# MM32P0xx register map
Vendor: MindMotion Ltd.; Series: MM32P0; File version: 1.4
MindMotion 32-bit Cortex-M0 Microcontroller based device, CPU clock up to 16 MHz, etc.
CPU: CM0 r0p0, little endian, no MPU, no FPU, 3 interrupt priority bits
Registers are 32-bit, read-write, reset 0x0 unless marked. A register's access mark holds for its fields unless they carry their own. Offsets are from the block's base; lines under a group give offsets from that group; [hi:lo] are bit positions; {n}, {i} and the like mark numbered series; 'fields as' and 'values as' point back to an identical list; <NAME> marks a mode.

## Memory map
0x40000000 TIM2 size 0x400 — General purpose timer
0x40000400 TIM3 size 0x400
0x40002C00 WWDG size 0x400 — Window watchdog
0x40003000 IWDG size 0x400 — Independent watchdog
0x40005400 I2C1 size 0x400 — Inter integrated circuit
0x40007000 PWR size 0x400 — Power control
0x40010000 SYSCFG size 0x400
0x40010400 EXTI size 0x400
0x40012400 ADC size 0x400 — Analog to digital converter
0x40012C00 TIM1 size 0x400 — Advanced timer
0x40013000 SPI1 size 0x400 — Serial peripheral interface
0x40013800 UART1 size 0x400 — Universal asynchronous receiver transmitter
0x40014000 TIM14 size 0x400 — Advanced timer
0x40014400 TIM16 size 0x400 — Advanced timer
0x40014800 TIM17 size 0x400
0x40020000 DMA size 0x400 — DMA controller
0x40021000 RCC size 0x400 — Reset and clock control
0x40022000 FLASH size 0x400
0x48000000 GPIOA size 0x400 — General purpose I/O
0x48000400 GPIOB size 0x400
0x48000800 GPIOC size 0x400
0x48000C00 GPIOD size 0x400
0xE0042000 DBG size 0x400 — Debug support

## Interrupts
0 WWDG — Window Watchdog interrupt
1 PVD (PWR) — PVD through EXTI line detection interrupt
3 FLASH — Flash global interrupt
4 RCC — RCC global interrupt
5 EXTI0_1 (EXTI) — EXTI Line0 interrupt
6 EXTI2_3 (EXTI) — EXTI Line1 interrupt
7 EXTI4_15 (EXTI) — EXTI Line2 interrupt
9 DMA_Channel1 (DMA) — DMA Channel1 global interrupt
10 DMA_Channel2 (DMA) — DMA Channel2 global interrupt
11 DMA_Channel4 (DMA) — DMA Channel4 global interrupt
12 ADC — ADC1 global interrupt
13 DMA_Channel3 (DMA) — DMA Channel3 global interrupt
14 TIM1_CC (TIM1) — TIM1 Capture Compare interrupt
19 TIM14_0 (TIM14) — TIM14 global interrupt
21 TIM14_1 (TIM14) — TIM14 global interrupt
22 TIM16 — TIM16 global interrupt
23 TIM17 — TIM17 global interrupt
25 SPI1 — SPI1 global interrupt
27 UART1 — UART1 global interrupt
28 TIM2 — TIM2 global interrupt
29 TIM3 — TIM3 global interrupt
31 I2C1_EV (I2C1) — I2C1 event interrupt

## SYSCFG
Base 0x40010000
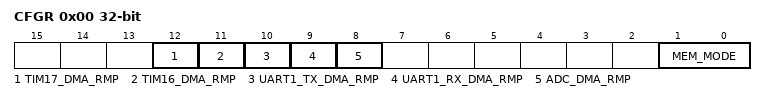
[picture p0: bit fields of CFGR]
0x00 CFGR
  [12] TIM17_DMA_RMP, [11] TIM16_DMA_RMP, [10] UART1_TX_DMA_RMP, [9] UART1_RX_DMA_RMP, [8] ADC_DMA_RMP, [1:0] MEM_MODE
{0x4+4i} EXTICR{i} (i=1..4)
  [15:0] EXTI{4i-1}

## EXTI
Base 0x40010400
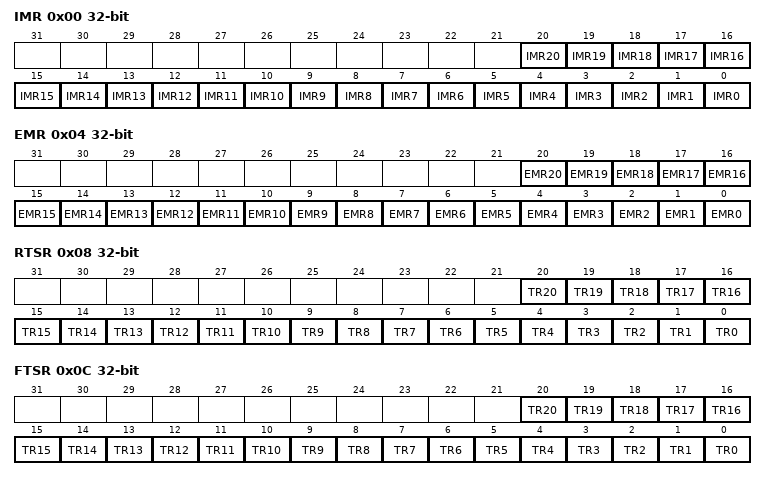
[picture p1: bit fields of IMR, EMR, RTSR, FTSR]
0x00 IMR
  [n] IMR{n} (n=0..20) — Interrupt Mask on line {n}
0x04 EMR
  [n] EMR{n} (n=0..20) — Event Mask on line {n}
0x08 RTSR
  [n] TR{n} (n=0..20) — Rising trigger event configuration bit of line {n}
0x0C FTSR
  [n] TR{n} (n=0..20) — Falling trigger event configuration bit of line {n}
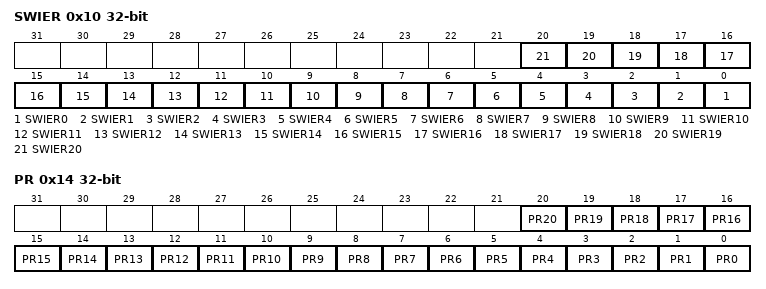
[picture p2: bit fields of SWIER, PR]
0x10 SWIER
  [n] SWIER{n} (n=0..20) — Software interrupt on line {n}
0x14 PR
  [n] PR{n} (n=0..20) — Pending bit

## DMA — DMA controller
Base 0x40020000
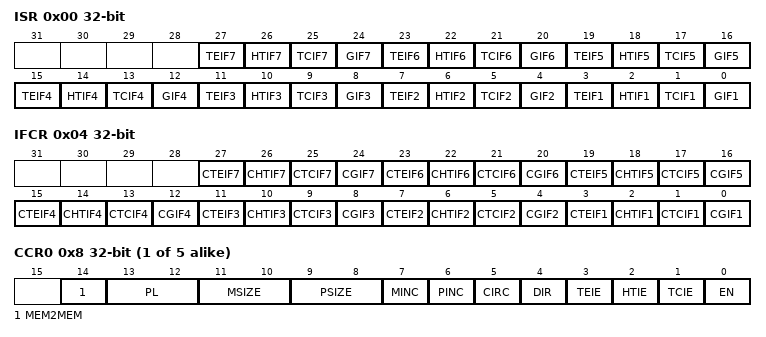
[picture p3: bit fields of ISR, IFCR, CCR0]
0x00 ISR ro
  [4n-1] TEIF{n} (n=1..7) — channel {n} transfer error flag
  [4n-2] HTIF{n} (n=1..7) — channel {n} half transfer flag
  [4n-3] TCIF{n} (n=1..7) — channel {n} half complete flag
  [4n-4] GIF{n} (n=1..7) — channel {n} global interrupt flag
0x04 IFCR ro
  [4n-1] CTEIF{n} (n=1..7) — channel {n} transfer error clear
  [4n-2] CHTIF{n} (n=1..7) — channel {n} half transfer clear
  [4n-3] CTCIF{n} (n=1..7) — channel {n} half complete clear
  [4n-4] CGIF{n} (n=1..7) — channel {n} global interrupt clear
{0x8+0x14*i} CCR{i} (i=0..4)
  [14] MEM2MEM — Memory to memory mode
  [13:12] PL — Channel priority level
  [11:10] MSIZE — Memory size
  [9:8] PSIZE — Peripheral size
  [7] MINC — Memory increment mode
  [6] PINC — Peripheral increment mode
  [5] CIRC — Circular mode
  [4] DIR — Data transfer direction
  [3] TEIE — Transfer error interrupt enable
  [2] HTIE — Half transfer interrupt enable
  [1] TCIE — Transfer complete interrupt enable
  [0] EN — Channel enable
{0xC+0x14*i} CNDTR{i} (i=0..4)
  [15:0] NDT — Number of data to transfer
{0x10+0x14*i} CPAR{i} (i=0..4)
  [31:0] PA — Peripheral address
{0x14+0x14*i} CMAR{i} (i=0..4)
  [31:0] MA — Memory address

## Licence text in the file
MindMotion Limited (MindMotion) is supplying this software for use with Cortex-M0!
